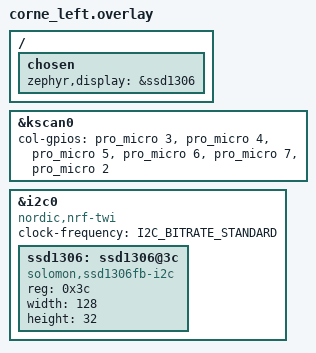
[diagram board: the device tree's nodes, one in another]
#include "corne.dtsi"

&kscan0 {
    col-gpios = <&pro_micro 3 GPIO_ACTIVE_HIGH>,
                <&pro_micro 4 GPIO_ACTIVE_HIGH>,
                <&pro_micro 5 GPIO_ACTIVE_HIGH>,
                <&pro_micro 6 GPIO_ACTIVE_HIGH>,
                <&pro_micro 7 GPIO_ACTIVE_HIGH>,
                <&pro_micro 2 GPIO_ACTIVE_HIGH>;
};

/ {
    chosen {
        zephyr,display = &ssd1306;
    };
};

&i2c0 {
    compatible = "nordic,nrf-twi";
    status = "okay";
    clock-frequency = <I2C_BITRATE_STANDARD>;

    ssd1306: ssd1306@3c {
        compatible = "solomon,ssd1306fb-i2c";
        reg = <0x3c>;
        width = <128>;
        height = <32>;
    };
};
